# field_bit_range_processing register map
File version: 1.0
Test_Example device
CPU: CM0 r0p0, little endian, no MPU, no FPU, 4 interrupt priority bits
Registers are access not given, no defined reset value unless marked. A register's access mark holds for its fields unless they carry their own. Offsets are from the block's base; lines under a group give offsets from that group; [hi:lo] are bit positions; {n}, {i} and the like mark numbered series; 'fields as' and 'values as' point back to an identical list; <NAME> marks a mode.

## Memory map
0x40001000 PeripheralA size 0x1000

## PeripheralA
Base 0x40001000
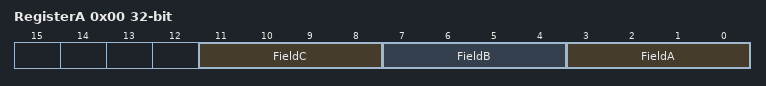
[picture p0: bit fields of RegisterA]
0x00 RegisterA
  [11:8] FieldC, [7:4] FieldB, [3:0] FieldA
